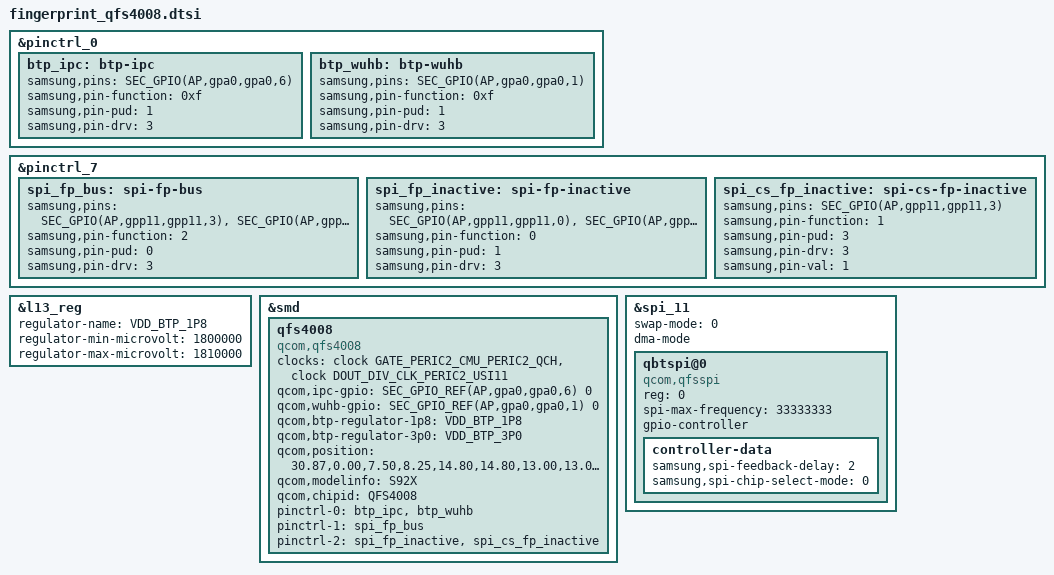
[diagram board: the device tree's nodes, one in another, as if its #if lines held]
&pinctrl_0 {
	btp_ipc: btp-ipc {
		samsung,pins = SEC_GPIO(AP,gpa0,gpa0,6);
		samsung,pin-function = <0xf>;
		samsung,pin-pud = <1>;
		samsung,pin-drv = <3>;
	};
};

&pinctrl_0 {
	btp_wuhb: btp-wuhb {
		samsung,pins = SEC_GPIO(AP,gpa0,gpa0,1);
		samsung,pin-function = <0xf>;
		samsung,pin-pud = <1>;
		samsung,pin-drv = <3>;
	};
};

&pinctrl_7 {
	spi_fp_bus: spi-fp-bus {
		samsung,pins = SEC_GPIO(AP,gpp11,gpp11,3), SEC_GPIO(AP,gpp11,gpp11,0), SEC_GPIO(AP,gpp11,gpp11,1), SEC_GPIO(AP,gpp11,gpp11,2);
		samsung,pin-function = <2>;
		samsung,pin-pud = <0>;
		samsung,pin-drv = <3>;
	};

	spi_fp_inactive: spi-fp-inactive {
		samsung,pins = SEC_GPIO(AP,gpp11,gpp11,0), SEC_GPIO(AP,gpp11,gpp11,1), SEC_GPIO(AP,gpp11,gpp11,2);
		samsung,pin-function = <0>;
		samsung,pin-pud = <1>;
		samsung,pin-drv = <3>;
	};

	spi_cs_fp_inactive: spi-cs-fp-inactive {
		samsung,pins = SEC_GPIO(AP,gpp11,gpp11,3);
		samsung,pin-function = <1>;
		samsung,pin-pud = <3>;
		samsung,pin-drv = <3>;
		samsung,pin-val = <1>;
	};
};

&l13_reg {
	regulator-name = "VDD_BTP_1P8";
	regulator-min-microvolt = <1800000>;
	regulator-max-microvolt = <1810000>;
};

#if 0
&${fps_regul_vdd_3p0} {
	regulator-name = "VDD_BTP_3P0";
	regulator-min-microvolt = <3000000>;
	regulator-max-microvolt = <3010000>;
};
#endif

&smd {
	qfs4008 {
		compatible = "qcom,qfs4008";
#if !defined(CONFIG_SEC_FACTORY) && 1
		clocks = <&clock GATE_PERIC2_CMU_PERIC2_QCH>, <&clock DOUT_DIV_CLK_PERIC2_USI11>;
		clock-names = "gate_spi_clk", "ipclk_spi";
#endif
		qcom,ipc-gpio = <SEC_GPIO_REF(AP,gpa0,gpa0,6) 0>;
		qcom,wuhb-gpio = <SEC_GPIO_REF(AP,gpa0,gpa0,1) 0>;
		qcom,btp-regulator-1p8 = "VDD_BTP_1P8";
		qcom,btp-regulator-3p0 = "VDD_BTP_3P0";
		qcom,position = "30.87,0.00,7.50,8.25,14.80,14.80,13.00,13.00,5.00";
		qcom,modelinfo = "S92X";
		qcom,chipid = "QFS4008";
		pinctrl-names = "default", "pins_poweron", "pins_poweroff";
		pinctrl-0 = <&btp_ipc &btp_wuhb>;
		pinctrl-1 = <&spi_fp_bus>;
		pinctrl-2 = <&spi_fp_inactive &spi_cs_fp_inactive>;
	};
};

#if defined(CONFIG_SEC_FACTORY) || !1
&spi_11 {
	status = "okay";
	pinctrl-names = "";
	swap-mode = <0>;
	dma-mode;

	qbtspi@0 {
		compatible = "qcom,qfsspi";
		reg = <0>;
		spi-max-frequency = <33333333>;

		gpio-controller;
		#gpio-cells = <2>;
		controller-data {
			samsung,spi-feedback-delay = <2>;
			samsung,spi-chip-select-mode = <0>;
		};
	};
};
#endif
